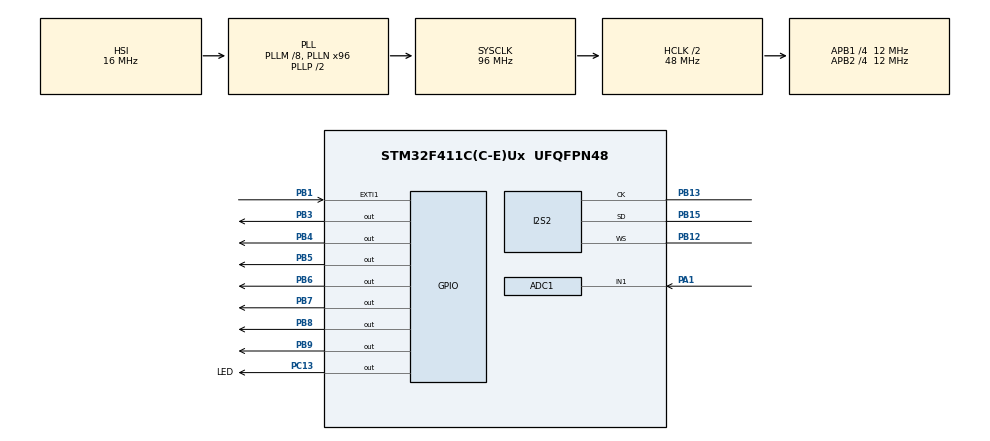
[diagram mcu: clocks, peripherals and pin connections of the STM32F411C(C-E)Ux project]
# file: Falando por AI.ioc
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ADC1.Channel-0\#ChannelRegularConversion=ADC_CHANNEL_1
ADC1.DMAContinuousRequests=ENABLE
ADC1.ExternalTrigConv=ADC_EXTERNALTRIGCONV_T2_TRGO
ADC1.NbrOfConversionFlag=1
ADC1.Rank-0\#ChannelRegularConversion=1
ADC1.SamplingTime-0\#ChannelRegularConversion=ADC_SAMPLETIME_3CYCLES
ADC1.master=1
Dma.ADC1.0.Direction=DMA_PERIPH_TO_MEMORY
Dma.ADC1.0.FIFOMode=DMA_FIFOMODE_DISABLE
Dma.ADC1.0.Instance=DMA2_Stream0
Dma.ADC1.0.MemDataAlignment=DMA_MDATAALIGN_HALFWORD
Dma.ADC1.0.MemInc=DMA_MINC_ENABLE
Dma.ADC1.0.Mode=DMA_NORMAL
Dma.ADC1.0.PeriphDataAlignment=DMA_PDATAALIGN_HALFWORD
Dma.ADC1.0.PeriphInc=DMA_PINC_DISABLE
Dma.ADC1.0.Priority=DMA_PRIORITY_LOW
Dma.Request0=ADC1
Dma.Request1=SPI2_TX
Dma.SPI2_TX.1.Direction=DMA_MEMORY_TO_PERIPH
Dma.SPI2_TX.1.FIFOMode=DMA_FIFOMODE_DISABLE
Dma.SPI2_TX.1.Instance=DMA1_Stream4
Dma.SPI2_TX.1.MemDataAlignment=DMA_MDATAALIGN_HALFWORD
Dma.SPI2_TX.1.MemInc=DMA_MINC_ENABLE
Dma.SPI2_TX.1.Mode=DMA_CIRCULAR
Dma.SPI2_TX.1.PeriphDataAlignment=DMA_PDATAALIGN_HALFWORD
Dma.SPI2_TX.1.PeriphInc=DMA_PINC_DISABLE
Dma.SPI2_TX.1.Priority=DMA_PRIORITY_LOW
I2S2.AudioFreq=I2S_AUDIOFREQ_48K
I2S2.DataFormat=I2S_DATAFORMAT_16B
I2S2.ErrorAudioFreq=-0.79 %
I2S2.FullDuplexMode=I2S_FULLDUPLEXMODE_DISABLE
I2S2.Instance=SPI$Index
I2S2.RealAudioFreq=47.619 KHz
I2S2.VirtualMode=I2S_MODE_MASTER
Mcu.Family=STM32F4
Mcu.Name=STM32F411C(C-E)Ux
Mcu.Package=UFQFPN48
NVIC.DMA1_Stream4_IRQn=true\:0\:0\:false\:false\:true\:false\:true\:true
NVIC.DMA2_Stream0_IRQn=true\:0\:0\:false\:false\:true\:false\:true\:true
NVIC.EXTI1_IRQn=true\:0\:0\:false\:false\:true\:true\:true\:true
NVIC.PriorityGroup=NVIC_PRIORITYGROUP_4
NVIC.TIM2_IRQn=true\:0\:0\:false\:false\:true\:true\:true\:true
PA1.Signal=ADCx_IN1
PB1.GPIO_PuPd=GPIO_PULLUP
PB1.Signal=GPXTI1
PB12.Mode=Half_Duplex_Master
PB12.Signal=I2S2_WS
PB13.Mode=Half_Duplex_Master
PB13.Signal=I2S2_CK
PB15.Mode=Half_Duplex_Master
PB15.Signal=I2S2_SD
PB3.Signal=GPIO_Output
PB4.Signal=GPIO_Output
PB5.Signal=GPIO_Output
PB6.Signal=GPIO_Output
PB7.Signal=GPIO_Output
PB8.Signal=GPIO_Output
PB9.Signal=GPIO_Output
PC13-ANTI_TAMP.GPIO_Label=LED
PC13-ANTI_TAMP.Signal=GPIO_Output
ProjectManager.HeapSize=0x200
ProjectManager.StackSize=0x400
ProjectManager.TargetToolchain=STM32CubeIDE
RCC.48MHZClocksFreq_Value=48000000
RCC.AHBCLKDivider=RCC_SYSCLK_DIV2
RCC.AHBFreq_Value=48000000
RCC.APB1CLKDivider=RCC_HCLK_DIV4
RCC.APB1Freq_Value=12000000
RCC.APB1TimFreq_Value=24000000
RCC.APB2CLKDivider=RCC_HCLK_DIV4
RCC.APB2Freq_Value=12000000
RCC.APB2TimFreq_Value=24000000
RCC.CortexFreq_Value=48000000
RCC.HCLKFreq_Value=48000000
RCC.HSE_VALUE=25000000
RCC.HSI_VALUE=16000000
RCC.LSE_VALUE=32768
RCC.PLLM=8
RCC.PLLN=96
RCC.SYSCLKFreq_VALUE=96000000
RCC.SYSCLKSource=RCC_SYSCLKSOURCE_PLLCLK
RCC.VCOOutputFreq_Value=192000000
SH.ADCx_IN1.0=ADC1_IN1,IN1
TIM2.Period=501
TIM2.TIM_MasterOutputTrigger=TIM_TRGO_UPDATE
VP_TIM2_VS_ClockSourceINT.Mode=Internal
board=custom

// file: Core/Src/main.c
/* USER CODE BEGIN Header */
/**
  ******************************************************************************
  * @file           : main.c
  * @brief          : Main program body
  ******************************************************************************
  * @attention
  *
  * Copyright (c) 2025 STMicroelectronics.
  * All rights reserved.
  *
  * This software is licensed under terms that can be found in the LICENSE file
  * in the root directory of this software component.
  * If no LICENSE file comes with this software, it is provided AS-IS.
  *
  ******************************************************************************
  */
/* USER CODE END Header */
#include "main.h"
#include "adc.h"
#include "dma.h"
#include "i2s.h"
#include "tim.h"
#include "gpio.h"

/* USER CODE BEGIN Includes */
#include "audio_processing.h"
#include "LCD1602.h"
/* USER CODE END Includes */

void SystemClock_Config(void);

int main(void)
{

  /* USER CODE BEGIN 1 */
  filters_init();
  /* USER CODE END 1 */

  /* MCU Configuration--------------------------------------------------------*/

  /* Reset of all peripherals, Initializes the Flash interface and the Systick. */
  HAL_Init();

  /* Configure the system clock */
  SystemClock_Config();

  /* Initialize all configured peripherals */
  MX_GPIO_Init();
  MX_DMA_Init();
  MX_ADC1_Init();
  MX_TIM2_Init();
  MX_I2S2_Init();
  /* USER CODE BEGIN 2 */
  HAL_TIM_Base_Start(&htim2);
  HAL_ADC_Start_DMA(&hadc1, (uint32_t*) IN_BUFFER, BUFFER_SIZE/2);
  HAL_I2S_Transmit_DMA(&hi2s2, (uint16_t*) OUT_BUFFER, BUFFER_SIZE*2);
  lcd_init();
  /* USER CODE END 2 */

  /* Infinite loop */
  while (1)
  {

  }
}

void SystemClock_Config(void)
{
  RCC_OscInitTypeDef RCC_OscInitStruct = {0};
  RCC_ClkInitTypeDef RCC_ClkInitStruct = {0};

  /** Configure the main internal regulator output voltage
  */
  __HAL_RCC_PWR_CLK_ENABLE();
  __HAL_PWR_VOLTAGESCALING_CONFIG(PWR_REGULATOR_VOLTAGE_SCALE1);

  /** Initializes the RCC Oscillators according to the specified parameters
  * in the RCC_OscInitTypeDef structure.
  */
  RCC_OscInitStruct.OscillatorType = RCC_OSCILLATORTYPE_HSI;
  RCC_OscInitStruct.HSIState = RCC_HSI_ON;
  RCC_OscInitStruct.HSICalibrationValue = RCC_HSICALIBRATION_DEFAULT;
  RCC_OscInitStruct.PLL.PLLState = RCC_PLL_ON;
  RCC_OscInitStruct.PLL.PLLSource = RCC_PLLSOURCE_HSI;
  RCC_OscInitStruct.PLL.PLLM = 8;
  RCC_OscInitStruct.PLL.PLLN = 96;
  RCC_OscInitStruct.PLL.PLLP = RCC_PLLP_DIV2;
  RCC_OscInitStruct.PLL.PLLQ = 4;
  if (HAL_RCC_OscConfig(&RCC_OscInitStruct) != HAL_OK)
  {
    Error_Handler();
  }

  /** Initializes the CPU, AHB and APB buses clocks
  */
  RCC_ClkInitStruct.ClockType = RCC_CLOCKTYPE_HCLK|RCC_CLOCKTYPE_SYSCLK
                              |RCC_CLOCKTYPE_PCLK1|RCC_CLOCKTYPE_PCLK2;
  RCC_ClkInitStruct.SYSCLKSource = RCC_SYSCLKSOURCE_PLLCLK;
  RCC_ClkInitStruct.AHBCLKDivider = RCC_SYSCLK_DIV2;
  RCC_ClkInitStruct.APB1CLKDivider = RCC_HCLK_DIV4;
  RCC_ClkInitStruct.APB2CLKDivider = RCC_HCLK_DIV4;

  if (HAL_RCC_ClockConfig(&RCC_ClkInitStruct, FLASH_LATENCY_1) != HAL_OK)
  {
    Error_Handler();
  }
}

void Error_Handler(void)
{
  __disable_irq();
  while (1)
  {
  }
}
